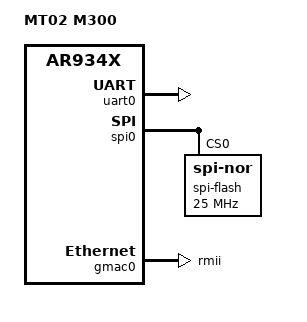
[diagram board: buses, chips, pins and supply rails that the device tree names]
// SPDX-License-Identifier: GPL-2.0+
/*
 * Copyright (C) 2024 Wojciech Cybowski <github.com/wcyb>
 */

/dts-v1/;
#include "ar934x.dtsi"

/ {
	model = "MT02 M300";
	compatible = "generic,mt02_m300_mt9341", "qca,ar934x";

	aliases {
		spi0 = &spi0;
		serial0 = &uart0;
	};

	chosen {
		stdout-path = "serial0:115200n8";
	};
};

&xtal {
	clock-frequency = <25000000>;
};

&uart0 {
	status = "okay";
	clock-frequency = <25000000>;
};

&spi0 {
	status = "okay";
	spi-max-frequency = <25000000>;
	spi-flash@0 {
		#address-cells = <1>;
		#size-cells = <1>;
		compatible = "jedec,spi-nor";
		memory-map = <0x9f000000 0x01000000>;
		spi-max-frequency = <25000000>;
		reg = <0>;
	};
};

&gmac0 {
	status = "okay";
	phy-mode = "rmii";
};
